# PIC16LF707 register map
Vendor: Microchip
Registers are 8-bit, read-write, reset 0x0 unless marked. A register's access mark holds for its fields unless they carry their own. Addresses are absolute, and some are shared; only a register's first bit layout is shown; [hi:lo] are bit positions; {n}, {i} and the like mark numbered series.

## SFR
0x00 INDF access not given
0x01 TMR0
0x02 PCL
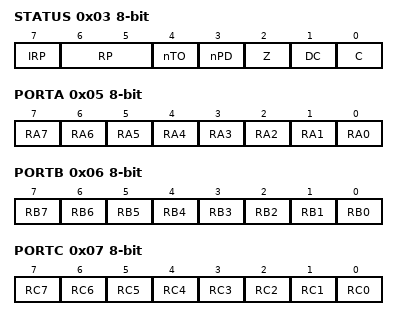
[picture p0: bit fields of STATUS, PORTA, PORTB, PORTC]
0x03 STATUS reset not defined — (power-on value 00011xxx)
  [7] IRP, [6:5] RP, [4] nTO ro, [3] nPD ro, [2] Z, [1] DC, [0] C
0x04 FSR reset not defined — (power-on value xxxxxxxx)
0x05 PORTA reset not defined — (power-on value xxxxxxxx)
  [n] RA{n} (n=0..7)
0x06 PORTB reset not defined — (power-on value xxxxxxxx)
  [n] RB{n} (n=0..7)
0x07 PORTC reset not defined — (power-on value xxxxxxxx)
  [n] RC{n} (n=0..7)
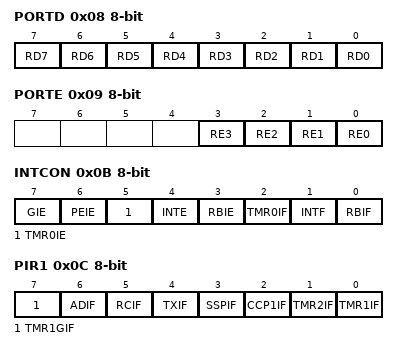
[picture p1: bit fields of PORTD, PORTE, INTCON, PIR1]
0x08 PORTD reset not defined — (power-on value xxxxxxxx)
  [n] RD{n} (n=0..7)
0x09 PORTE reset not defined — (power-on value ----xxxx)
  [3] RE3 ro, [2] RE2, [1] RE1, [0] RE0
0x0A PCLATH
  [4:0] PCLATH
0x0B INTCON reset not defined — (power-on value 0000000x)
  [7] GIE, [6] PEIE, [5] TMR0IE, [4] INTE, [3] RBIE, [2] TMR0IF, [1] INTF, [0] RBIF
0x0C PIR1
  [7] TMR1GIF, [6] ADIF, [5] RCIF ro, [4] TXIF ro, [3] SSPIF, [2] CCP1IF, [1] TMR2IF, [0] TMR1IF
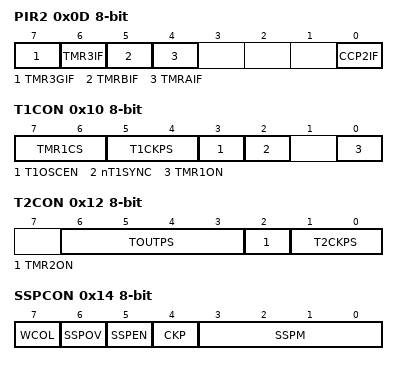
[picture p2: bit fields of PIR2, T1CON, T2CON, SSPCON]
0x0D PIR2
  [7] TMR3GIF, [6] TMR3IF, [5] TMRBIF, [4] TMRAIF, [0] CCP2IF
0x0E TMR1L reset not defined — (power-on value xxxxxxxx)
0x0F TMR1H reset not defined — (power-on value xxxxxxxx)
0x10 T1CON
  [7:6] TMR1CS, [5:4] T1CKPS, [3] T1OSCEN, [2] nT1SYNC, [0] TMR1ON
0x11 TMR2
0x12 T2CON
  [6:3] TOUTPS, [2] TMR2ON, [1:0] T2CKPS
0x13 SSPBUF reset not defined — (power-on value xxxxxxxx)
0x14 SSPCON
  [7] WCOL, [6] SSPOV, [5] SSPEN, [4] CKP, [3:0] SSPM
0x15 CCPR1L reset not defined — (power-on value xxxxxxxx)
0x16 CCPR1H reset not defined — (power-on value xxxxxxxx)
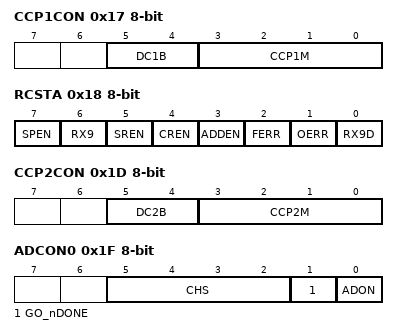
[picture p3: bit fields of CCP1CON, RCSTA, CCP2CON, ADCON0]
0x17 CCP1CON
  [5:4] DC1B, [3:0] CCP1M
0x18 RCSTA reset not defined — (power-on value 0000000x)
  [7] SPEN, [6] RX9, [5] SREN, [4] CREN, [3] ADDEN, [2] FERR ro, [1] OERR ro, [0] RX9D ro
0x19 TXREG
0x1A RCREG ro
0x1B CCPR2L reset not defined — (power-on value xxxxxxxx)
0x1C CCPR2H reset not defined — (power-on value xxxxxxxx)
0x1D CCP2CON
  [5:4] DC2B, [3:0] CCP2M
0x1E ADRES reset not defined — (power-on value xxxxxxxx)
0x1F ADCON0
  [5:2] CHS, [1] GO_nDONE, [0] ADON
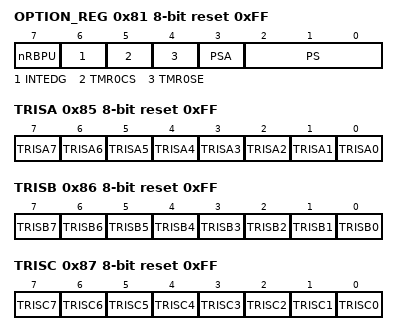
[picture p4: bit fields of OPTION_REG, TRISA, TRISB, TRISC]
0x81 OPTION_REG reset 0xFF
  [7] nRBPU, [6] INTEDG, [5] TMR0CS, [4] TMR0SE, [3] PSA, [2:0] PS
0x85 TRISA reset 0xFF
  [n] TRISA{n} (n=0..7)
0x86 TRISB reset 0xFF
  [n] TRISB{n} (n=0..7)
0x87 TRISC reset 0xFF
  [n] TRISC{n} (n=0..7)
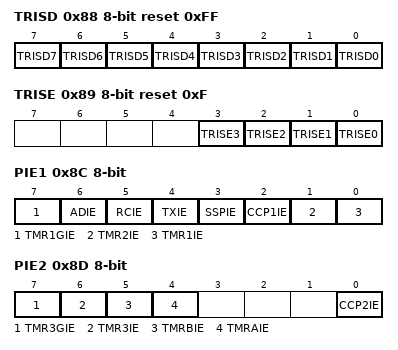
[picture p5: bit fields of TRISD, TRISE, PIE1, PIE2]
0x88 TRISD reset 0xFF
  [n] TRISD{n} (n=0..7)
0x89 TRISE reset 0xF
  [3] TRISE3 ro, [2] TRISE2, [1] TRISE1, [0] TRISE0
0x8C PIE1
  [7] TMR1GIE, [6] ADIE, [5] RCIE, [4] TXIE, [3] SSPIE, [2] CCP1IE, [1] TMR2IE, [0] TMR1IE
0x8D PIE2
  [7] TMR3GIE, [6] TMR3IE, [5] TMRBIE, [4] TMRAIE, [0] CCP2IE
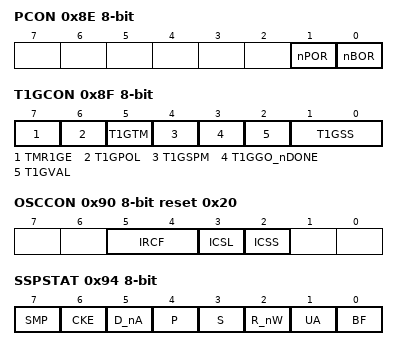
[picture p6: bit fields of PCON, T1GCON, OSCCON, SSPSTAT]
0x8E PCON reset not defined — (power-on value ------qq)
  [1] nPOR, [0] nBOR
0x8F T1GCON reset not defined — (power-on value 00000x00)
  [7] TMR1GE, [6] T1GPOL, [5] T1GTM, [4] T1GSPM, [3] T1GGO_nDONE, [2] T1GVAL ro, [1:0] T1GSS
0x90 OSCCON reset 0x20
  [5:4] IRCF, [3] ICSL ro, [2] ICSS ro
0x91 OSCTUNE
  [5:0] TUN
0x92 PR2 reset 0xFF
0x93 SSPADD
0x93 SSPMSK reset 0xFF
0x94 SSPSTAT
  [7] SMP, [6] CKE, [5] D_nA, [4] P, [3] S, [2] R_nW, [1] UA, [0] BF
0x95 WPUB reset 0xFF
0x96 IOCB
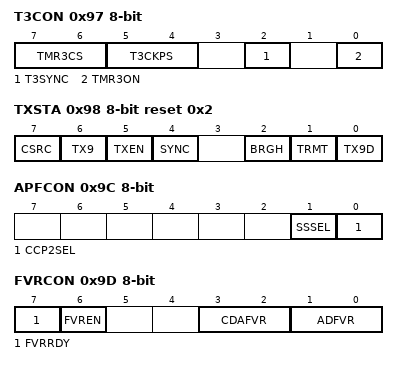
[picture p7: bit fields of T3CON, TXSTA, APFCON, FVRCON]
0x97 T3CON
  [7:6] TMR3CS, [5:4] T3CKPS, [2] T3SYNC, [0] TMR3ON
0x98 TXSTA reset 0x2
  [7] CSRC, [6] TX9, [5] TXEN, [4] SYNC, [2] BRGH, [1] TRMT ro, [0] TX9D
0x99 SPBRG
0x9A TMR3L reset not defined — (power-on value xxxxxxxx)
0x9B TMR3H reset not defined — (power-on value xxxxxxxx)
0x9C APFCON
  [1] SSSEL, [0] CCP2SEL
0x9D FVRCON reset not defined — (power-on value x0000000)
  [7] FVRRDY ro, [6] FVREN, [3:2] CDAFVR, [1:0] ADFVR
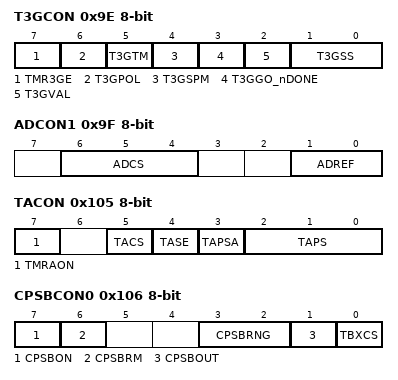
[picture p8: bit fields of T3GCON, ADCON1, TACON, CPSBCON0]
0x9E T3GCON reset not defined — (power-on value 00000x00)
  [7] TMR3GE, [6] T3GPOL, [5] T3GTM, [4] T3GSPM, [3] T3GGO_nDONE, [2] T3GVAL ro, [1:0] T3GSS
0x9F ADCON1
  [6:4] ADCS, [1:0] ADREF
0x105 TACON
  [7] TMRAON, [5] TACS, [4] TASE, [3] TAPSA, [2:0] TAPS
0x106 CPSBCON0
  [7] CPSBON, [6] CPSBRM, [3:2] CPSBRNG, [1] CPSBOUT ro, [0] TBXCS
0x107 CPSBCON1
  [3:0] CPSBCH
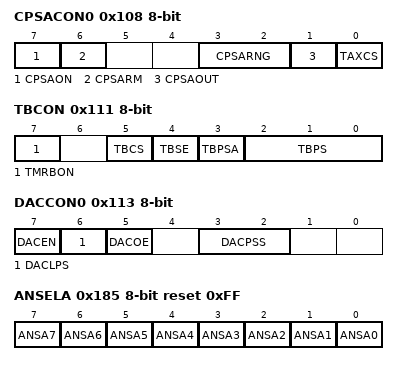
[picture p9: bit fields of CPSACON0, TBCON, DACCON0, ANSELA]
0x108 CPSACON0
  [7] CPSAON, [6] CPSARM, [3:2] CPSARNG, [1] CPSAOUT ro, [0] TAXCS
0x109 CPSACON1
  [3:0] CPSACH
0x10C PMDATL reset not defined — (power-on value xxxxxxxx)
0x10D PMADRL reset not defined — (power-on value xxxxxxxx)
0x10E PMDATH reset not defined — (power-on value --xxxxxx)
  [5:0] PMDATH
0x10F PMADRH reset not defined — (power-on value ---xxxxx)
  [4:0] PMADRH
0x110 TMRA
0x111 TBCON
  [7] TMRBON, [5] TBCS, [4] TBSE, [3] TBPSA, [2:0] TBPS
0x112 TMRB
0x113 DACCON0
  [7] DACEN, [6] DACLPS, [5] DACOE, [3:2] DACPSS
0x114 DACCON1
  [4:0] DACR
0x185 ANSELA reset 0xFF
  [n] ANSA{n} (n=0..7)
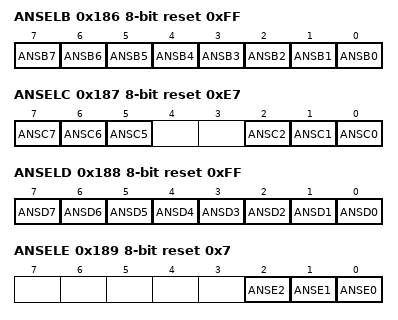
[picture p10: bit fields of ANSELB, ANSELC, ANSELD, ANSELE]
0x186 ANSELB reset 0xFF
  [n] ANSB{n} (n=0..7)
0x187 ANSELC reset 0xE7
  [7] ANSC7, [6] ANSC6, [5] ANSC5, [2] ANSC2, [1] ANSC1, [0] ANSC0
0x188 ANSELD reset 0xFF
  [n] ANSD{n} (n=0..7)
0x189 ANSELE reset 0x7
  [2] ANSE2, [1] ANSE1, [0] ANSE0
0x18C PMCON1 reset 0x80
  [0] RD
